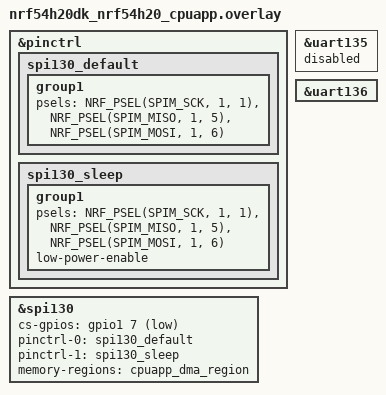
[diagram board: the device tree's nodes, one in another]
/*
 * Copyright (c) 2025 Nordic Semiconductor
 *
 * SPDX-License-Identifier: LicenseRef-Nordic-5-Clause
 */

#include "../nrf7002eb2_gpio_pins_2.dtsi"

&pinctrl {
	spi130_default: spi130_default {
		group1 {
			psels = <NRF_PSEL(SPIM_SCK,  1, 1)>,
				<NRF_PSEL(SPIM_MISO, 1, 5)>,
				<NRF_PSEL(SPIM_MOSI, 1, 6)>;
		};
	};

	spi130_sleep: spi130_sleep {
		group1 {
			psels = <NRF_PSEL(SPIM_SCK,  1, 1)>,
				<NRF_PSEL(SPIM_MISO, 1, 5)>,
				<NRF_PSEL(SPIM_MOSI, 1, 6)>;
			low-power-enable;
		};
	};
};

&spi130 {
	status = "okay";
	cs-gpios = <&gpio1 7 GPIO_ACTIVE_LOW>;
	pinctrl-0 = <&spi130_default>;
	pinctrl-1 = <&spi130_sleep>;
	pinctrl-names = "default", "sleep";
	memory-regions = <&cpuapp_dma_region>;
};

&uart135 {
	status = "disabled";
};

&uart136 {
	status = "okay";
};
